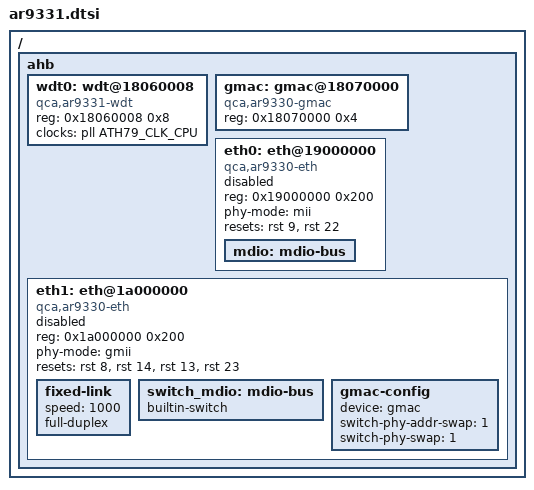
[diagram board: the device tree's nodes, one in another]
/ {
	ahb {
		wdt0: wdt@18060008 {
			compatible = "qca,ar9331-wdt", "qca,ar9344-wdt";
			reg = <0x18060008 0x8>;
			clocks = <&pll ATH79_CLK_CPU>;
		};

		gmac: gmac@18070000 {
			compatible = "qca,ar9330-gmac";
			reg = <0x18070000 0x4>;
		};

		eth0: eth@19000000 {
			status = "disabled";

			compatible = "qca,ar9330-eth";
			reg = <0x19000000 0x200>;

			phy-mode = "mii";

			resets = <&rst 9>, <&rst 22>;
			reset-names = "mac", "mdio";

			mdio: mdio-bus {
				status = "okay";
			};
		};

		eth1: eth@1a000000 {
			status = "disabled";

			compatible = "qca,ar9330-eth";
			reg = <0x1a000000 0x200>;

			phy-mode = "gmii";
			
			resets = <&rst 8>, <&rst 14>, <&rst 13>, <&rst 23>;
			reset-names = "esw", "esw_analog", "mac", "mdio";

			fixed-link {
				speed = <1000>;
				full-duplex;
			};

			switch_mdio: mdio-bus {
				status = "okay";

				builtin-switch;
			};

			gmac-config {
				device = <&gmac>;

				switch-phy-addr-swap = <1>;
				switch-phy-swap = <1>;
			};
		};
	};
};
